# pac52xx_sfr register map
Registers from a debugger description file.
Registers are 32-bit, access not given, no defined reset value unless marked. A register's access mark holds for its fields unless they carry their own. Addresses are absolute; registers are grouped by the start of their names; lines under a group give offsets from that group; [hi:lo] are bit positions; {n}, {i} and the like mark numbered series; 'fields as' and 'values as' point back to an identical list; <NAME> marks a mode.

## SFR
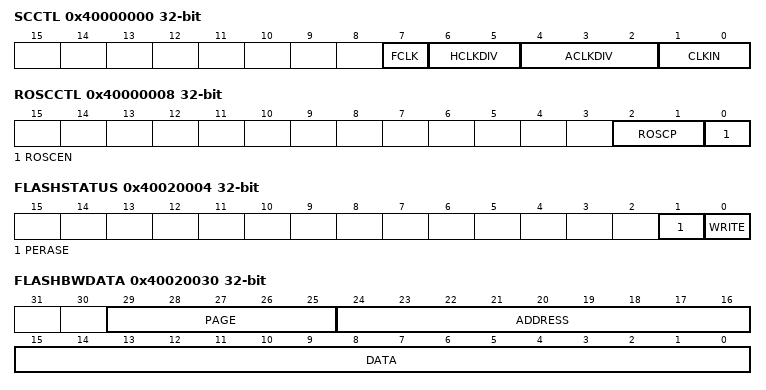
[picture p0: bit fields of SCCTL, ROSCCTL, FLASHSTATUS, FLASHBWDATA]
0x40000000 SCCTL
  [7] FCLK, [6:5] HCLKDIV, [4:2] ACLKDIV, [1:0] CLKIN
0x40000004 PLLCTL
  [15:7] PLLFBDIV, [19:6] PLLOUTDIV, [6:2] PLLINDIV, [0] PLLEN
0x40000008 ROSCCTL
  [2:1] ROSCP, [0] ROSCEN
0x4000000C XTALCTL
0x40020000 FLASHLOCK
  [31:0] LOCK
0x40020004 FLASHSTATUS
  [1] PERASE, [0] WRITE
0x40020008 FLASHPAGE
  [4:0] PAGE
0x40020014 FLASHPERASE
  [31:0] PERASE
0x40020024 SWDACCESS
  [16:0] DEBUG
0x40020028 FLASHWSTATE
  [1:0] WSTATE
0x4002002C FLASHBWRITE
  [31:0] BWRITE
0x40020030 FLASHBWDATA
  [29:25] PAGE, [24:16] ADDRESS, [15:0] DATA
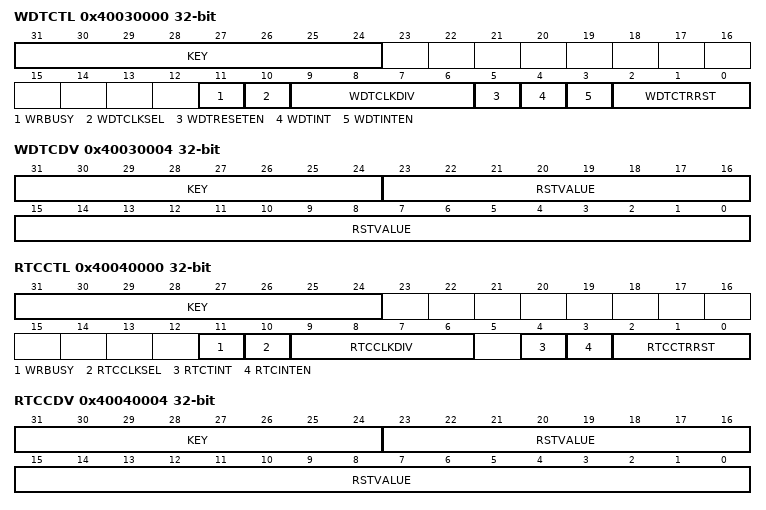
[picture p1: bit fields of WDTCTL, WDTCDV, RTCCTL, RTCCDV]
0x40030000 WDTCTL
  [31:24] KEY, [11] WRBUSY, [10] WDTCLKSEL, [9:6] WDTCLKDIV, [5] WDTRESETEN, [4] WDTINT, [3] WDTINTEN, [2:0] WDTCTRRST
0x40030004 WDTCDV
  [31:24] KEY, [23:0] RSTVALUE
0x40030008 WDTCTR
  [23:0] CTR
0x40040000 RTCCTL
  [31:24] KEY, [11] WRBUSY, [10] RTCCLKSEL, [9:6] RTCCLKDIV, [4] RTCTINT, [3] RTCINTEN, [2:0] RTCCTRRST
0x40040004 RTCCDV
  [31:24] KEY, [23:0] RSTVALUE
0x40040008 RTCCTR
  [23:0] CTR
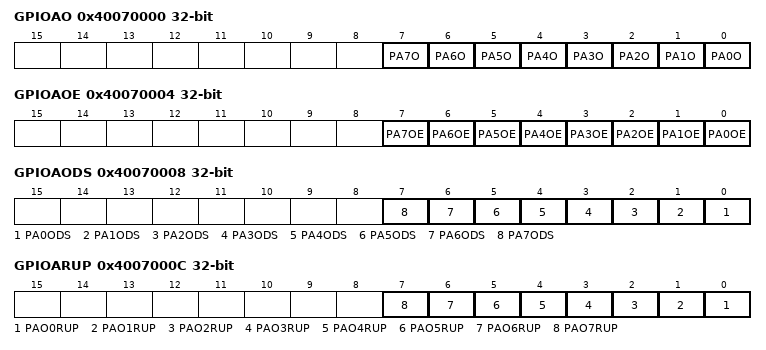
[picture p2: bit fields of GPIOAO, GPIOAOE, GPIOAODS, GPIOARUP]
0x40070000 GPIOAO
  [n] PA{n}O (n=0..7)
0x40070004 GPIOAOE
  [n] PA{n}OE (n=0..7)
0x40070008 GPIOAODS
  [n] PA{n}ODS (n=0..7)
0x4007000C GPIOARUP
  [n] PAO{n}RUP (n=0..7)
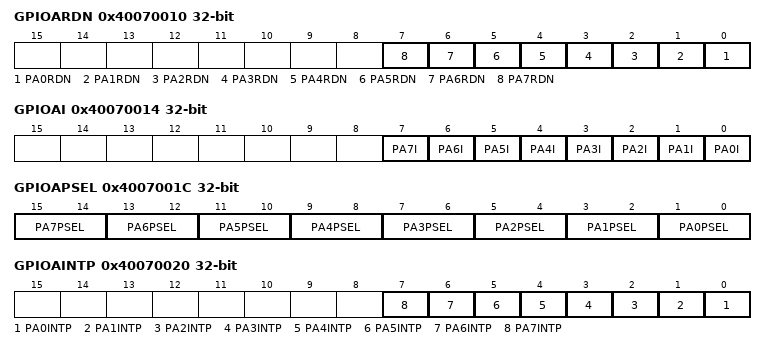
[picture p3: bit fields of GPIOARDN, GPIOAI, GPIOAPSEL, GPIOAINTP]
0x40070010 GPIOARDN
  [n] PA{n}RDN (n=0..7)
0x40070014 GPIOAI
  [n] PA{n}I (n=0..7)
0x4007001C GPIOAPSEL
  [2n+1:2n] PA{n}PSEL (n=0..7)
0x40070020 GPIOAINTP
  [n] PA{n}INTP (n=0..7)
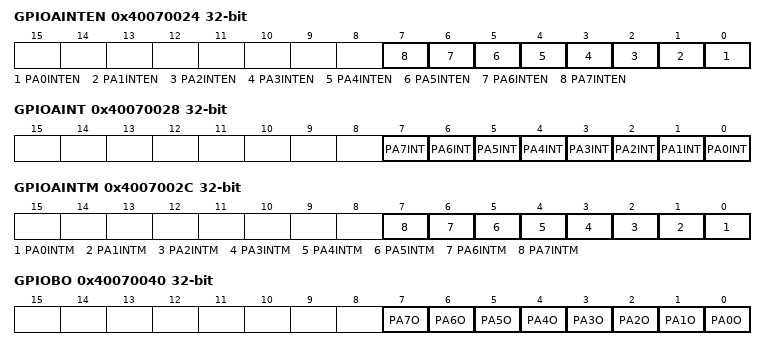
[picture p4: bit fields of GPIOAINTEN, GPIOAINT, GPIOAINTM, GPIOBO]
0x40070024 GPIOAINTEN
  [n] PA{n}INTEN (n=0..7)
0x40070028 GPIOAINT
  [n] PA{n}INT (n=0..7)
0x4007002C GPIOAINTM
  [n] PA{n}INTM (n=0..7)
0x40070040 GPIOBO
  [n] PA{n}O (n=0..7)
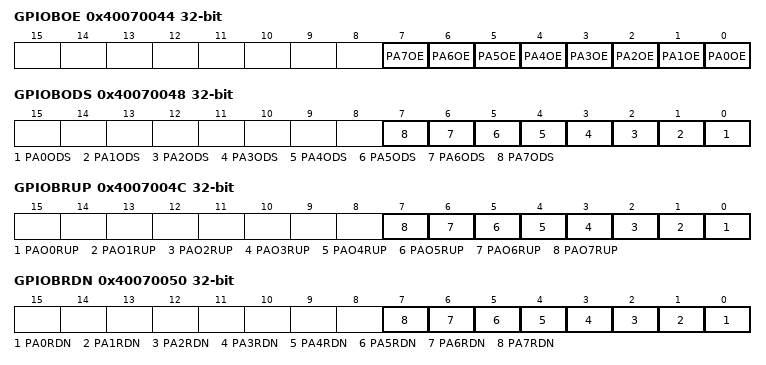
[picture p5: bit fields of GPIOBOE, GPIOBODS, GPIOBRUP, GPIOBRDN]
0x40070044 GPIOBOE
  [n] PA{n}OE (n=0..7)
0x40070048 GPIOBODS
  [n] PA{n}ODS (n=0..7)
0x4007004C GPIOBRUP
  [n] PAO{n}RUP (n=0..7)
0x40070050 GPIOBRDN
  [n] PA{n}RDN (n=0..7)
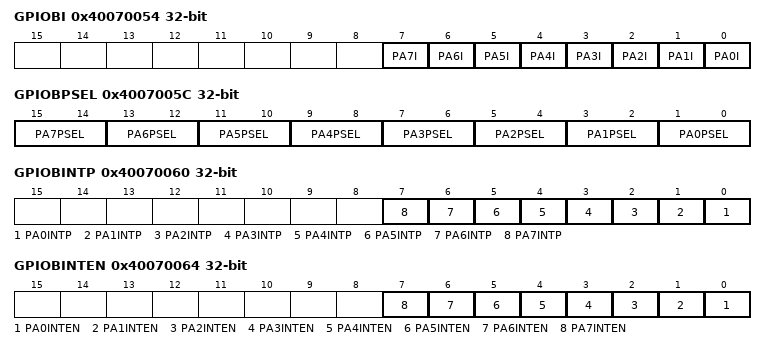
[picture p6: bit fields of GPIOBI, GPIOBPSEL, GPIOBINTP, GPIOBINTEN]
0x40070054 GPIOBI
  [n] PA{n}I (n=0..7)
0x4007005C GPIOBPSEL
  [2n+1:2n] PA{n}PSEL (n=0..7)
0x40070060 GPIOBINTP
  [n] PA{n}INTP (n=0..7)
0x40070064 GPIOBINTEN
  [n] PA{n}INTEN (n=0..7)
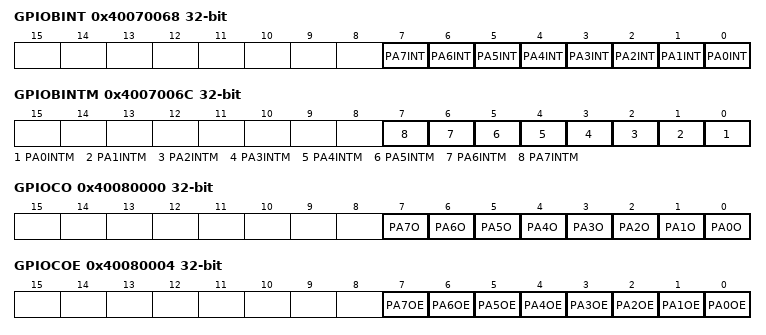
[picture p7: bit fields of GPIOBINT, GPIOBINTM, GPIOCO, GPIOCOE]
0x40070068 GPIOBINT
  [n] PA{n}INT (n=0..7)
0x4007006C GPIOBINTM
  [n] PA{n}INTM (n=0..7)
0x40080000 GPIOCO
  [n] PA{n}O (n=0..7)
0x40080004 GPIOCOE
  [n] PA{n}OE (n=0..7)
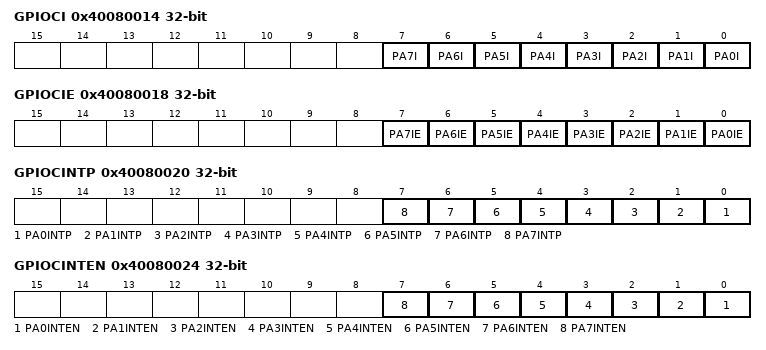
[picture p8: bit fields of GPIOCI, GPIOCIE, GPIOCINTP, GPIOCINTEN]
0x40080014 GPIOCI
  [n] PA{n}I (n=0..7)
0x40080018 GPIOCIE
  [n] PA{n}IE (n=0..7)
0x40080020 GPIOCINTP
  [n] PA{n}INTP (n=0..7)
0x40080024 GPIOCINTEN
  [n] PA{n}INTEN (n=0..7)
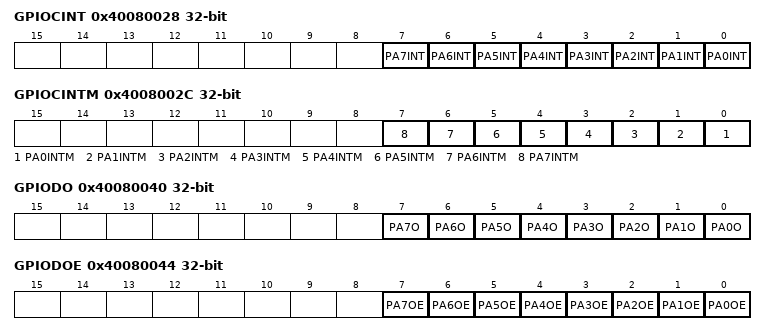
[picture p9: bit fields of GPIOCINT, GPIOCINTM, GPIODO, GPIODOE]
0x40080028 GPIOCINT
  [n] PA{n}INT (n=0..7)
0x4008002C GPIOCINTM
  [n] PA{n}INTM (n=0..7)
0x40080040 GPIODO
  [n] PA{n}O (n=0..7)
0x40080044 GPIODOE
  [n] PA{n}OE (n=0..7)
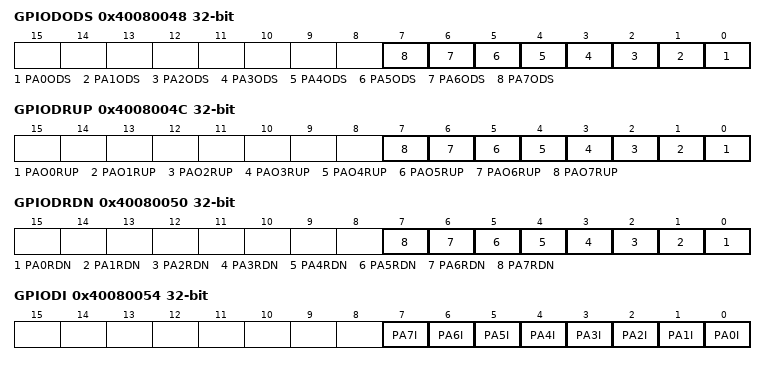
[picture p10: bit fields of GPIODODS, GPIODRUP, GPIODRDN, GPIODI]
0x40080048 GPIODODS
  [n] PA{n}ODS (n=0..7)
0x4008004C GPIODRUP
  [n] PAO{n}RUP (n=0..7)
0x40080050 GPIODRDN
  [n] PA{n}RDN (n=0..7)
0x40080054 GPIODI
  [n] PA{n}I (n=0..7)
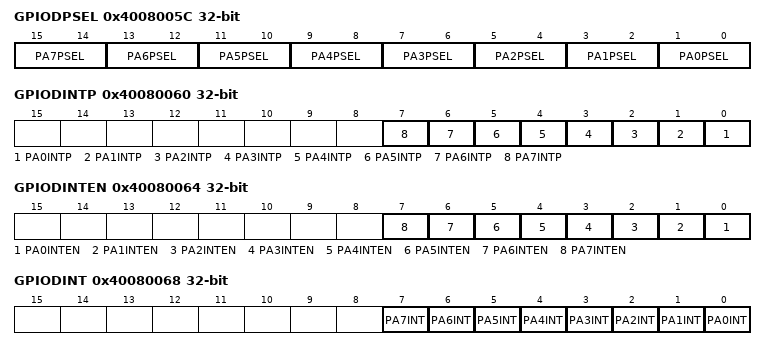
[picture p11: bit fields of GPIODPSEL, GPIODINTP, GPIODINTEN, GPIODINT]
0x4008005C GPIODPSEL
  [2n+1:2n] PA{n}PSEL (n=0..7)
0x40080060 GPIODINTP
  [n] PA{n}INTP (n=0..7)
0x40080064 GPIODINTEN
  [n] PA{n}INTEN (n=0..7)
0x40080068 GPIODINT
  [n] PA{n}INT (n=0..7)
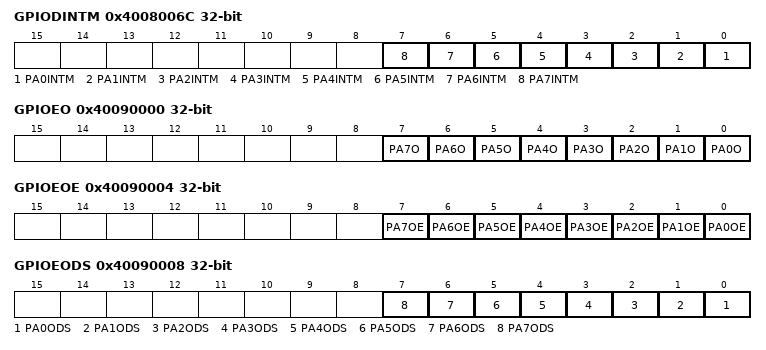
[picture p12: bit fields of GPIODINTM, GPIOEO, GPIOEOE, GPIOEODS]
0x4008006C GPIODINTM
  [n] PA{n}INTM (n=0..7)
0x40090000 GPIOEO
  [n] PA{n}O (n=0..7)
0x40090004 GPIOEOE
  [n] PA{n}OE (n=0..7)
0x40090008 GPIOEODS
  [n] PA{n}ODS (n=0..7)
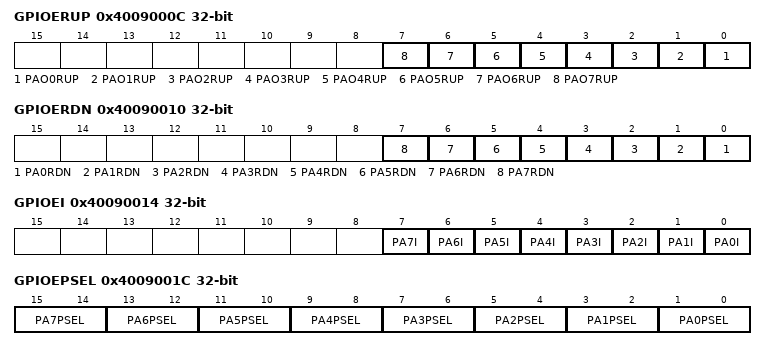
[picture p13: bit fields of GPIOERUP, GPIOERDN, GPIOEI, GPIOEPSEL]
0x4009000C GPIOERUP
  [n] PAO{n}RUP (n=0..7)
0x40090010 GPIOERDN
  [n] PA{n}RDN (n=0..7)
0x40090014 GPIOEI
  [n] PA{n}I (n=0..7)
0x4009001C GPIOEPSEL
  [2n+1:2n] PA{n}PSEL (n=0..7)
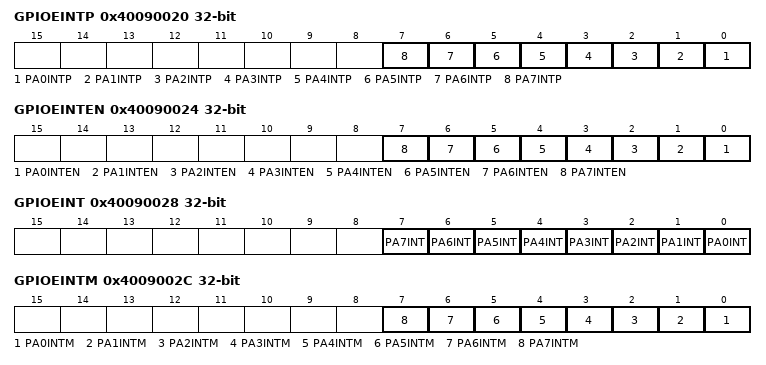
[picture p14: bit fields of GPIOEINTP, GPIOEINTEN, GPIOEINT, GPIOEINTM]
0x40090020 GPIOEINTP
  [n] PA{n}INTP (n=0..7)
0x40090024 GPIOEINTEN
  [n] PA{n}INTEN (n=0..7)
0x40090028 GPIOEINT
  [n] PA{n}INT (n=0..7)
0x4009002C GPIOEINTM
  [n] PA{n}INTM (n=0..7)
0x400D0000 TACTL
  [13] DTGCLK, [11:10] MODE, [9] CLK, [8:6] CLKDIV, [5] INTEN, [4] INT, [3] SS, [2] CLR, [0] PRDL
0x400D0004 TAPRD
  [15:0] PERIOD
0x400D0008 TACTR
  [15:0] CTR
{0x400D0040+8i} TACC{i}CTL (i=0..7)
  [4] CCMODE, [3] CCINTEN, [2] CCINT, [1:0] CCEDG
{0x400D0044+8i} TACC{i}CTR (i=0..7)
  [15:0] CCCTR
{0x400D00A0+0x10*i} DTGA{i}CTL (i=0..3)
  [7] BYPASS, [6] OTP, [5] INVHS, [4] INVLS
{0x400D00A4+0x10*i} DTGA{i}LED (i=0..3)
  [11:0] LED
{0x400D00A8+0x10*i} DTGA{i}TED (i=0..3)
  [11:0] TED
0x400E0000 TBCTL
  fields as TACTL
0x400E0004 TBPRD
  [15:0] PERIOD
0x400E0008 TBCTR
  [15:0] CTR
{0x400E0040+8i} TBCC{i}CTL (i=0..3)
  [4] CCMODE, [3] CCINTEN, [2] CCINT, [1:0] CCEDG
{0x400E0044+8i} TBCC{i}CTR (i=0..3)
  [15:0] CCCTR
0x400E00A0 DTGB0CTL
  [7] BYPASS, [6] OTP, [5] INVHS, [4] INVLS
0x400E00A4 DTGB0LED
  [11:0] LED
0x400E00A8 DTGB0TED
  [11:0] TED
0x400F0000 TCCTL
  fields as TACTL
0x400F0004 TCPRD
  [15:0] PERIOD
0x400F0008 TCCTR
  [15:0] CTR
0x400F0040 TCCC0CTL
  [4] CCMODE, [3] CCINTEN, [2] CCINT, [1:0] CCEDG
0x400F0044 TCCC0CTR
  [15:0] CCCTR
0x400F0048 TCCC1CTL
  [4] CCMODE, [3] CCINTEN, [2] CCINT, [1:0] CCEDG
0x400F004C TCCC1CTR
  [15:0] CCCTR
0x400F00A0 DTGC0CTL
  [7] BYPASS, [6] OTP, [5] INVHS, [4] INVLS
0x400F00A4 DTGC0LED
  [11:0] LED
0x400F00A8 DTGC0TED
  [11:0] TED
0x40100000 TDCTL
  fields as TACTL
0x40100004 TDPRD
  [15:0] PERIOD
0x40100008 TDCTR
  [15:0] CTR
0x40100040 TDCC0CTL
  [4] CCMODE, [3] CCINTEN, [2] CCINT, [1:0] CCEDG
0x40100044 TDCC0CTR
  [15:0] CCCTR
0x40100048 TDCC1CTL
  [4] CCMODE, [3] CCINTEN, [2] CCINT, [1:0] CCEDG
0x4010004C TDCC1CTR
  [15:0] CCCTR
0x401000A0 DTGD0CTL
  [7] BYPASS, [6] OTP, [5] INVHS, [4] INVLS
0x401000A4 DTGD0LED
  [11:0] LED
0x401000A8 DTGD0TED
  [11:0] TED
0x40150000 EMUXCTL
  [5] EMUXC, [4] EMUXBUSY, [3] EMUXDONE, [2:0] CMUXCDIV
0x40150004 EMUXDATA
  [7:0] DATA
0x40150008 ADCCTL
  [15] ADCEN, [14] ADCSTART, [13] ADCREPEAT, [12:10] ADCMODE, [7] ADCBUSY, [6:4] ADCMUX, [3] ADCDONE, [2:0] ADCCDIV
0x4015000C ADCCR
  [9:0] ADCRESULT
0x40150010 ADCINT
  [19:18] ASCINTTR, [17:16] ASCINTSEQ, [12] ASCINT_EN, [11] AS1INT_EN, [10] AS0INT_EN, [9] EMUXINT_EN, [8] ADCINT_EN, [4] ASCINT, [3] AS1INT, [2] AS0INT, [1] EMUXINT, [0] ADCINT
0x40150040 AS0CTL
  [12] AS0BUSY, [11] AS0EN, [10:8] AS0D, [7] AS0TR, [6] AS0TRE, [5:4] AS0TRTMR, [3:0] ASA0TRPWM
{0x40150044+8i} AS0S{i} (i=0..7)
  [14:12] ADCMUX, [11:10] DELAY, [9:8] EMUXS, [7:0] EMUXD
{0x40150048+8i} AS0R{i} (i=0..7)
  [9:0] ADCRESULT
0x40150100 AS1CTL
  [12] AS1BUSY, [11] AS1EN, [10:8] AS1D, [7] AS1TR, [6] AS1TRE, [5:4] AS1TRTMR, [3:0] ASA0TRPWM
{0x40150104+8i} AS1S{i} (i=0..7)
  [14:12] ADCMUX, [11:10] DELAY, [9:8] EMUXS, [7:0] EMUXD
{0x40150108+8i} AS1R{i} (i=0..7)
  [9:0] ADCRESULT
0x401B0000 I2CCFG
  [5] PFILTER, [4] ADDRMODE, [2] MAEN, [0] SLEN
0x401B0004 I2CINT
  [24] SLXVERDONEINT, [18] SLRXFINT, [17] SLTXEINT, [16] SLADDRMINT, [11] MADACKINT, [10] MAARBLINT, [9] MAADDRACKINT, [8] MAXFERDONEINT, [2] MARXF, [1] MACTLE, [0] MATXE
0x401B0008 I2CINTEN
  [24] SLXFERDONEINTEN, [18] SLRXF, [17] SLTXE, [16] SLADDRM, [8] MAXFERDONE, [2] MARXF, [1] MACTLE, [0] MATXE
0x401B0030 I2CMCTL
  [13] I2CMACTLF, [11] XFERTYPE, [10] RSTART, [9:7] I2CADDRU, [6:0] I2CADDRL
0x401B0034 I2CMARXDATA
  [8] I2CMARXDATAF, [7:0] MARXDATA
0x401B0038 I2CMATXDATA
  [9] LBYTE, [8] I2CMATXDATAF, [7:0] MATXDATA
0x401B0040 I2CBAUD
  [26:16] SCLH, [7:0] SCLL
0x401B0070 I2CSRXDATA
  [8] I2CSLRXDATAF, [7:0] SLRXDATA
0x401B0074 I2CSLTXDATA
  [9] I2CSLTXDATAF, [8] NACK, [7:0] SLTXDATA
0x401B0078 I2CSLADDR
  [9:7] ALADDRH, [6:0] SLADDRL
0x401D0000 UARTRXTX
  [7:0] RXTX
0x401D0004 UARTIEN
  [3] MSITNEN, [2] RSINTEN, [1] TXINTEN, [0] RXINTEN
0x401D0008 UARTII
  [7] RXFEN, [6] TXFEN, [3:1] UARTINTID, [0] UARTINT
0x401D000C UARTLC
  [6] SB, [5] SP, [4] EPS, [3] PEN, [2] STB, [1:0] BPC
0x401D0014 UARTLS
  [7] RXE, [6] TXE, [5] TCFE, [4] RXBE, [3] RXFE, [2] RXPE, [1] RXOE, [0] RXDR
0x401D001C UARTSP
  [7:0] SP
0x401D0020 UARTFCTL
  [7:6] RXFT, [2] TXFRESET, [1] RXFRESET, [0] FEN
0x401D0040 UARTFSTAT
  [3] RXFF, [2] RXFE, [1] TXFF, [0] TXFE
0x40200000 SOCBCTL
  [1] SIE, [0] SSEN
0x40200004 SOCBCFG
  [2] MRST
0x40200008 SOCBCLKDIV
  [15:0] CLKDIV
0x40200014 SOCBSTAT
  [14:12] CURSTATE, [10] RXFULL, [9] TXFULL, [8] WRUFL, [5] CYC_DONE, [2] RDOFL, [0] SOCB_INT
0x40200018 SOCBCSSTR
  [19:16] CSWAIT, [15:12] CSHOLD, [11:8] CSSETUP
0x4020001C SOCBD
  [7:0] DATA
0x40200020 SOCBINT_EN
  [8] WRUFL_EN, [5] CYC_DONE_EN, [2] RDOFL_EN
0x40210000 SPICTL
  [8] RTRANS, [7] MMST_N, [6] MTRANS, [5] MTRARM, [3] SE, [2] LPBK, [1] SIE, [0] SSEN
0x40210004 SPICFG
  [13] BP_MTRANS, [12] BP_EN, [11] MTURBO, [10] TXDBUF, [9] TXDAT_PH, [7] RCVCPH, [6] RCVCP, [5] CPH, [4] CP, [3] LB1ST, [2] MRST, [1:0] WL
0x40210008 SPICLKDIV
  [15:0] CLKDIV
0x40210014 SPISTAT
  [14:12] CURSTATE, [10] RXFULL, [9] TXFULL, [8] WRUFL, [7] BP_DONE, [6] TE, [5] CYC_DONE, [4] UCLK, [3] LE, [2] RDOFL, [0] SPI_INT
0x40210018 SPICSSTR
  [23:20] CKWAIT, [19:16] CSWAIT, [15:12] CSHOLD, [11:8] CSSETUP, [2] CSL, [1:0] CSNUM
0x4021001C SPID
  [31:0] DATA
0x40210020 SPIINT_EN
  [8] WRUFL_EN, [7] BP_DONE, [6] TE_EN, [5] CYC_DONE_EN, [4] UCLK_EN, [3] LE_EN, [2] RDOFL_EN
0xE000E100 ISER
  [n] SETENA{n} (n=0..31)
0xE000E180 ICER
  [n] CLRENA{n} (n=0..31)
0xE000E200 ISPR
  [n] SETPEND{n} (n=0..31)
0xE000E280 ICPR
  [n] CLRPEND{n} (n=0..31)
0xE000E400 IPR0
  [8n+7:8n] PRI_{n} (n=0..3)
0xE000E404 IPR1
  [8n-25:8n-32] PRI_{n} (n=4..7)
0xE000E408 IPR2
  [8n-57:8n-64] PRI_{n} (n=8..11)
0xE000E40C IPR3
  [8n-89:8n-96] PRI_{n} (n=12..15)
0xE000E410 IPR4
  [8n-121:8n-128] PRI_{n} (n=16..19)
0xE000E414 IPR5
  [8n-153:8n-160] PRI_{n} (n=20..23)
0xE000E418 IPR6
  [8n-185:8n-192] PRI_{n} (n=24..27)
0xE000E41C IPR7
  [31:24] PRI_31, [23:16] PRI_30, [15:8] PRI_29, [7:0] PRI_20
0xE000ED00 CPUIDBR
  [31:24] IMPLEMENTER, [23:20] VARIANT, [19:16] CONSTANT, [15:4] PARTNO, [3:0] REVISION
0xE000ED00 CPUID
  fields as CPUIDBR
0xE000ED04 ICSR
  [31] NMIPENDSET, [28] PENDSVSET, [27] PENDSVCLR, [26] PENDSTSET, [25] PENDSTCLR, [22] ISRPENDING, [17:12] VECTPENDING, [5:0] VECTACTIVE
0xE000ED0C AIRCR
  [31:16] VECTKEY, [15] ENDIANESS, [2] SYSRESETREQ, [1] VECTCLRACTIVE
0xE000ED10 SCR
  [4] SEVONPEND, [2] SLEEPDEEP, [1] SLEEPONEXIT
0xE000ED14 CCR
  [8] STKALIGN, [3] UNALIGN_TRP
0xE000ED1C SHPR2
  [31:24] PRI_11
0xE000ED20 SHPR3
  [31:24] PRI_15, [23:16] PRI_14

## UARTDL
0x401D0028 UARTDL_L
  [7:0] DL_L
0x401D002C UARTDL_H
  [7:0] DL_H

## UARTFD
0x401D0038 UARTFD_F
  [7:0] FRAC
0x401D003C UARTFD_CTL
  [7] FDCLK
